# M480_v1 register map
File version: 1.0
Registers are 32-bit, read-write, reset 0x0 unless marked. A register's access mark holds for its fields unless they carry their own. Offsets are from the block's base; [hi:lo] are bit positions; {n}, {i} and the like mark numbered series; 'fields as' and 'values as' point back to an identical list.

## PDMA — PDMA Register Map
Base 0x40008000; alternate view of DSCT_CTL
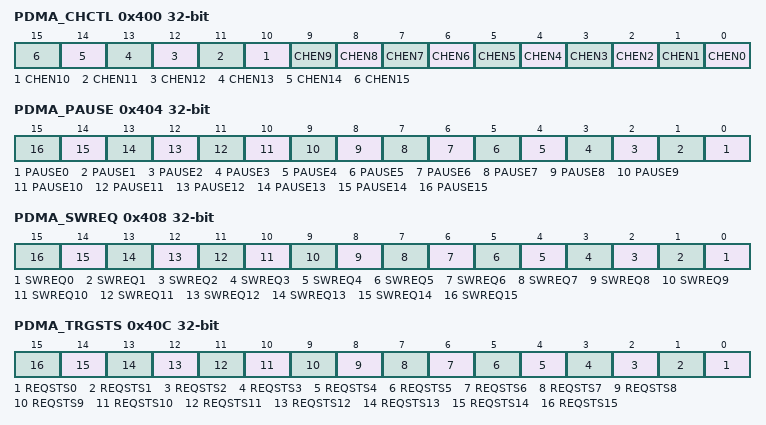
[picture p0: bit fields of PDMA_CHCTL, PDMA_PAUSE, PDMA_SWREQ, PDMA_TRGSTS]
0x400 PDMA_CHCTL — PDMA Channel Control Register
  [all] fields
    0=PDMA channel [n] Disabled; 1=PDMA channel [n] Enabled
  [n] CHEN{n} (n=0..15) — PDMA Channel Enable Bits. Set this bit to 1 to enable PDMAn operation. Channel cannot be active if it is not set as enabled. Note: Setting the corresponding bit of PDMA_PAUSE or PDMA_CHRST register will also clear this bit.
0x404 PDMA_PAUSE wo — PDMA Transfer Pause Control Register
  [all] fields
    0=No effect; 1=Pause PDMA channel n transfer
  [n] PAUSE{n} (n=0..15) — PDMA Channel n Transfer Pause Control (Write Only)
0x408 PDMA_SWREQ wo — PDMA Software Request Register
  [all] fields
    0=No effect; 1=Generate a software request
  [n] SWREQ{n} (n=0..15) — PDMA Software Request (Write Only). Set this bit to 1 to generate a software request to PDMA [n]. Note 1: User can read PDMA_TRGSTS register to know which channel is on active. Active flag may be triggered by software request or peripheral request. Note 2: If user does not enable corresponding PDMA channel, the software request will be ignored.
0x40C PDMA_TRGSTS ro — PDMA Channel Request Status Register
  [all] fields
    0=PDMA Channel n has no request; 1=PDMA Channel n has a request
  [n] REQSTS{n} (n=0..15) — PDMA Channel Request Status (Read Only). This flag indicates whether channel[n] have a request or not, no matter request from software or peripheral. When PDMA controller finishes channel transfer, this bit will be cleared automatically. Note: If user pauses or resets each PDMA transfer by setting PDMA_PAUSE or PDMA_CHRST register respectively, this bit will be cleared automatically after finishing the current transfer.
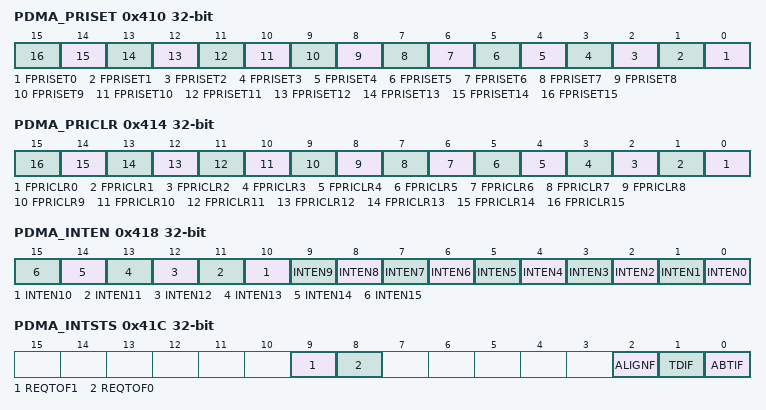
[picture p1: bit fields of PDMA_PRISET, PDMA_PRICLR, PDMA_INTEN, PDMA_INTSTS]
0x410 PDMA_PRISET — PDMA Fixed Priority Setting Register
  [all] fields
    0=No effect. Corresponding PDMA channel is round-robin priority; 1=Set PDMA channel [n] to fixed priority channel. Corresponding PDMA channel is fixed priority
  [n] FPRISET{n} (n=0..15) — PDMA Fixed Priority Setting. Set this bit to 1 to enable fixed priority level. Write Operation: Note: This field only set to fixed priority, clear fixed priority use PDMA_PRICLR register.
0x414 PDMA_PRICLR wo — PDMA Fixed Priority Clear Register
  [all] fields
    0=No effect; 1=Clear PDMA channel [n] fixed priority setting
  [n] FPRICLR{n} (n=0..15) — PDMA Fixed Priority Clear Bits (Write Only). Set this bit to 1 to clear fixed priority level. Note: User can read PDMA_PRISET register to know the channel priority.
0x418 PDMA_INTEN — PDMA Interrupt Enable Register
  [all] fields
    0=PDMA channel n interrupt Disabled; 1=PDMA channel n interrupt Enabled.Note: The interrupt flag is time-out, abort, transfer done and align
  [n] INTEN{n} (n=0..15) — PDMA Interrupt Enable Bits. This field is used to enable PDMA channel[n] interrupt.
0x41C PDMA_INTSTS — PDMA Interrupt Status Register
  [9] REQTOF1 — Request Time-out Flag for Channel 1. This flag indicates that PDMA controller has waited peripheral request for a period defined by PDMA_TOC1, user can write 1 to clear these bits. Note: Please disable time-out function before clear this bit.
    0=No request time-out; 1=Peripheral request time-out
  [8] REQTOF0 — Request Time-out Flag for Channel 0. This flag indicates that PDMA controller has waited peripheral request for a period defined by PDMA_TOC0, user can write 1 to clear these bits. Note: Please disable time-out function before clear this bit.
    0=No request time-out; 1=Peripheral request time-out
  [2] ALIGNF ro — Transfer Alignment Interrupt Flag (Read Only)
    0=PDMA channel source address and destination address both follow transfer width setting; 1=PDMA channel source address or destination address is not follow transfer width setting
  [1] TDIF ro — Transfer Done Interrupt Flag (Read Only). This bit indicates that PDMA controller has finished transmission; User can read PDMA_TDSTS register to indicate which channel finished transfer.
    0=Not finished yet; 1=PDMA channel has finished transmission
  [0] ABTIF ro — PDMA Read/Write Target Abort Interrupt Flag (Read Only). This bit indicates that PDMA has target abort error; Software can read PDMA_ABTSTS register to find which channel has target abort error.
    0=No AHB bus ERROR response received; 1=AHB bus ERROR response received
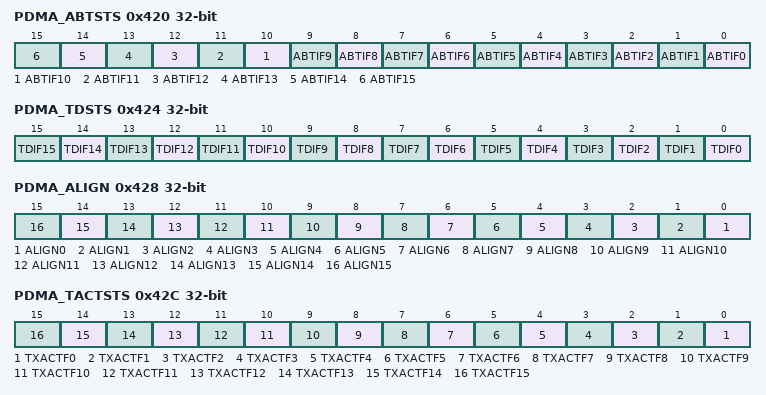
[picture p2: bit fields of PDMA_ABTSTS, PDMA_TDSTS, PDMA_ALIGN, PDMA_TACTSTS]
0x420 PDMA_ABTSTS — PDMA Channel Read/Write Target Abort Flag Register
  [all] fields
    0=No AHB bus ERROR response received when channel n transfer; 1=AHB bus ERROR response received when channel n transfer
  [n] ABTIF{n} (n=0..15) — PDMA Read/Write Target Abort Interrupt Status Flag. This bit indicates which PDMA controller has target abort error; User can write 1 to clear these bits. Note: If channel n target abort, REQSRCn should set 0 to disable peripheral request.
0x424 PDMA_TDSTS — PDMA Channel Transfer Done Flag Register
  [all] fields
    0=PDMA channel transfer has not finished; 1=PDMA channel has finished transmission
  [n] TDIF{n} (n=0..15) — Transfer Done Flag. This bit indicates whether PDMA controller channel transfer has been finished or not, user can write 1 to clear these bits.
0x428 PDMA_ALIGN — PDMA Transfer Alignment Status Register
  [all] fields
    values as PDMA_INTSTS.ALIGNF
  [n] ALIGN{n} (n=0..15) — Transfer Alignment Flag. Note: Source address and destination address should be alignment.
0x42C PDMA_TACTSTS ro — PDMA Transfer Active Flag Register
  [all] fields
    0=PDMA channel is not finished; 1=PDMA channel is active
  [n] TXACTF{n} (n=0..15) — Transfer on Active Flag (Read Only). This bit indicates which PDMA channel is in active.
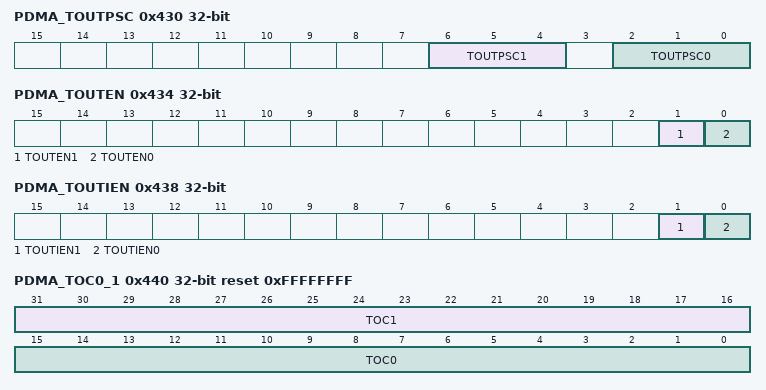
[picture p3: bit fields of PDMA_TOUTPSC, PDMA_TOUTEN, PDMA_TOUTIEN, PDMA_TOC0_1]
0x430 PDMA_TOUTPSC — PDMA Time-out Prescaler Register
  [6:4] TOUTPSC1 — PDMA Channel 1 Time-out Clock Source Prescaler Bits
    0=PDMA channel 1 time-out clock source is HCLK/28; 1=PDMA channel 1 time-out clock source is HCLK/29; {v}=PDMA channel 1 time-out clock source is HCLK/{v+208} (v=2..7)
  [2:0] TOUTPSC0 — PDMA Channel 0 Time-out Clock Source Prescaler Bits
    0=PDMA channel 0 time-out clock source is HCLK/28; 1=PDMA channel 0 time-out clock source is HCLK/29; {v}=PDMA channel 0 time-out clock source is HCLK/{v+208} (v=2..7)
0x434 PDMA_TOUTEN — PDMA Time-out Enable Register
  [1] TOUTEN1 — PDMA Time-out Enable Bits
    0=PDMA Channel n time-out function Disabled; 1=PDMA Channel n time-out function Enabled
  [0] TOUTEN0 — PDMA Time-out Enable Bits
    values as TOUTEN1
0x438 PDMA_TOUTIEN — PDMA Time-out Interrupt Enable Register
  [1] TOUTIEN1 — PDMA Time-out Interrupt Enable Bits
    0=PDMA Channel n time-out interrupt Disabled; 1=PDMA Channel n time-out interrupt Enabled
  [0] TOUTIEN0 — PDMA Time-out Interrupt Enable Bits
    values as TOUTIEN1
0x43C PDMA_SCATBA reset 0x20000000 — PDMA Scatter-gather Descriptor Table Base Address Register
  [31:16] SCATBA — PDMA Scatter-gather Descriptor Table Address. In Scatter-Gather mode, this is the base address for calculating the next link - list address. The next link address equation is. Note: Only useful in Scatter-Gather mode.
0x440 PDMA_TOC0_1 reset 0xFFFFFFFF — PDMA Time-out Counter Ch1 and Ch0 Register
  [31:16] TOC1 — Time-out Counter for Channel 1. This controls the period of time-out function for channel 1. The calculation unit is based on 10 kHz clock. The example of time-out period can refer TOC0 bit description.
  [15:0] TOC0 — Time-out Counter for Channel 0. This controls the period of time-out function for channel 0. The calculation unit is based on TOUTPSC0 (PDMA_TOUTPSC[2:0]) clock.
0x460 PDMA_CHRST — PDMA Channel Reset Register
  [15:0] CHnRST — Channel n Reset. Note: This function don't support stride mode.
    0=corresponding channel n is not reset; 1=corresponding channel n is reset
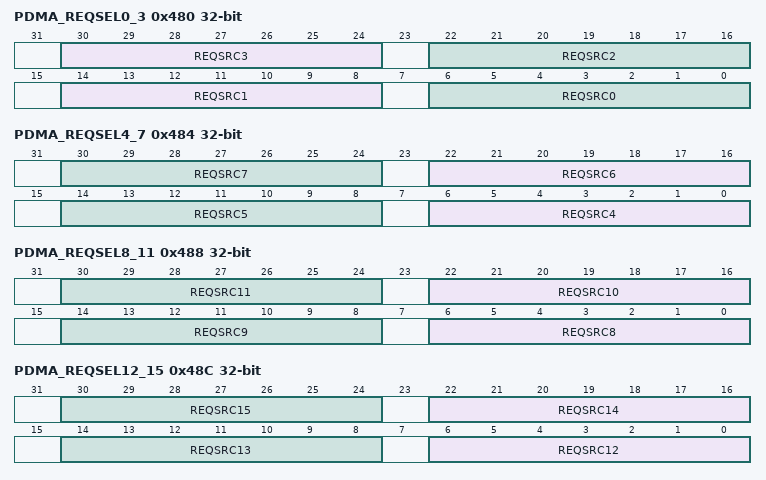
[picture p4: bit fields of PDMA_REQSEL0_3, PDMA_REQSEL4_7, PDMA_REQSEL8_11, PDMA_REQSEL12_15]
0x480 PDMA_REQSEL0_3 — PDMA Request Source Select Register 0
  [30:24] REQSRC3 — Channel 3 Request Source Selection. This filed defines which peripheral is connected to PDMA channel 3. User can configure the peripheral setting by REQSRC3. Note: The channel configuration is the same as REQSRC0 field. Please refer to the explanation of REQSRC0.
  [22:16] REQSRC2 — Channel 2 Request Source Selection. This filed defines which peripheral is connected to PDMA channel 2. User can configure the peripheral setting by REQSRC2. Note: The channel configuration is the same as REQSRC0 field. Please refer to the explanation of REQSRC0.
  [14:8] REQSRC1 — Channel 1 Request Source Selection. This filed defines which peripheral is connected to PDMA channel 1. User can configure the peripheral setting by REQSRC1. Note: The channel configuration is the same as REQSRC0 field. Please refer to the explanation of REQSRC0.
  [6:0] REQSRC0 — Channel 0 Request Source Selection. This filed defines which peripheral is connected to PDMA channel 0. User can configure the peripheral by setting REQSRC0. Note 1: A peripheral cannot be assigned to two channels at the same time. Note 2: This field is useless when transfer between memory and memory.
    0=Disable PDMA peripheral request; 2=Channel connects to USB_TX; 3=Channel connects to USB_RX; 4=Channel connects to UART0_TX; 5=Channel connects to UART0_RX; 6=Channel connects to UART1_TX; 7=Channel connects to UART1_RX; 8=Channel connects to UART2_TX; 9=Channel connects to UART2_RX; 10=Channel connects to UART3_TX; 11=Channel connects to UART3_RX; 12=Channel connects to UART4_TX; 13=Channel connects to UART4_RX; 14=Channel connects to UART5_TX; 15=Channel connects to UART5_RX; 16=Channel connects to USCI0_TX; 17=Channel connects to USCI0_RX; 18=Channel connects to USCI1_TX; 19=Channel connects to USCI1_RX; 20=Channel connects to QSPI0_TX; 21=Channel connects to QSPI0_RX; 22=Channel connects to SPI0_TX; 23=Channel connects to SPI0_RX; 24=Channel connects to SPI1_TX; 25=Channel connects to SPI1_RX; 26=Channel connects to SPI2_TX; 27=Channel connects to SPI2_RX; 28=Channel connects to SPI3_TX; 29=Channel connects to SPI3_RX; 30=Channel connects to QSPI1_TX; 31=Channel connects to QSPI1_RX; 32=Channel connects to EPWM0_P1_RX; 33=Channel connects to EPWM0_P2_RX; 34=Channel connects to EPWM0_P3_RX; 35=Channel connects to EPWM1_P1_RX; 36=Channel connects to EPWM1_P2_RX; 37=Channel connects to EPWM1_P3_RX; 38=Channel connects to I2C0_TX; 39=Channel connects to I2C0_RX; 40=Channel connects to I2C1_TX; 41=Channel connects to I2C1_RX; 42=Channel connects to I2C2_TX; 43=Channel connects to I2C2_RX; 44=Channel connects to I2S0_TX; 45=Channel connects to I2S0_RX; {v}=Channel connects to TMR{v-46} (v=46..49); 50=Channel connects to EADC0_RX; 51=Channel connects to DAC0_TX; 52=Channel connects to DAC1_TX; {v}=Channel connects to EPWM0_CH{v-53}_TX (v=53..58); {v}=Channel connects to EPWM1_CH{v-59}_TX (v=59..64); 66=Channel connects to UART6_TX; 67=Channel connects to UART6_RX; 68=Channel connects to UART7_TX; 69=Channel connects to UART7_RX; 70=Channel connects to EADC1_RX
0x484 PDMA_REQSEL4_7 — PDMA Request Source Select Register 1
  [8n-26:8n-32] REQSRC{n} (n=4..7) — Channel {n} Request Source Selection. This filed defines which peripheral is connected to PDMA channel {n}. User can configure the peripheral setting by REQSRC{n}. Note: The channel configuration is the same as REQSRC0 field. Please refer to the explanation of REQSRC0.
0x488 PDMA_REQSEL8_11 — PDMA Request Source Select Register 2
  [8n-58:8n-64] REQSRC{n} (n=8..11) — Channel {n} Request Source Selection. This filed defines which peripheral is connected to PDMA channel {n}. User can configure the peripheral setting by REQSRC{n}. Note: The channel configuration is the same as REQSRC0 field. Please refer to the explanation of REQSRC0.
0x48C PDMA_REQSEL12_15 — PDMA Request Source Select Register 3
  [8n-90:8n-96] REQSRC{n} (n=12..15) — Channel {n} Request Source Selection. This filed defines which peripheral is connected to PDMA channel {n}. User can configure the peripheral setting by REQSRC{n}. Note: The channel configuration is the same as REQSRC0 field. Please refer to the explanation of REQSRC0.
{0x500+8i} PDMA_STC{i} (i=0..5) — Stride Transfer Count Register of PDMA Channel {i}
  [15:0] STC — PDMA Stride Transfer Count. The 16-bit register defines the stride transfer count of each row, the real transfer count is (STC + 1).
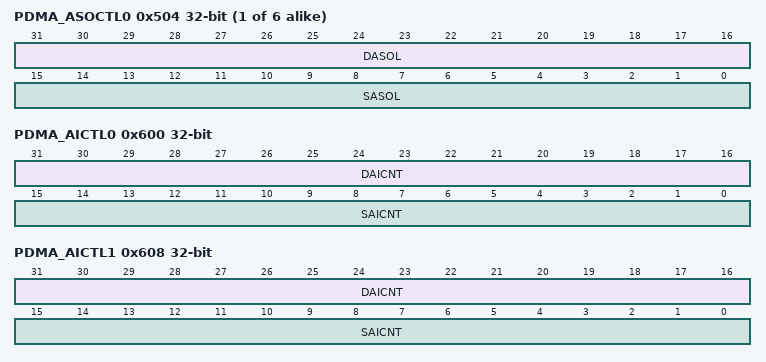
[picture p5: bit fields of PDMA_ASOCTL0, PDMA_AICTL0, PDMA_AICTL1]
{0x504+8i} PDMA_ASOCTL{i} (i=0..5) — Address Stride Offset Control Register of PDMA Channel {i}
  [31:16] DASOL — PDMA Destination Address Stride Offset Length. The 16-bit register defines the destination address stride transfer offset count of each row.
  [15:0] SASOL — PDMA Source Address Stride Offset Length. The 16-bit register defines the source address stride transfer offset count of each row.
0x600 PDMA_AICTL0 — Address Interval Control Register of PDMA Channel 0
  [31:16] DAICNT — PDMA Destination Address Interval Count. The 16-bit register defines the destination address interval count of each row. Note: This register should be set to 0 when repeat count(PDMA_RCNTn) set to 0.
  [15:0] SAICNT — PDMA Source Address Interval Count. The 16-bit register defines the source address interval count of each row. Note: This register should be set to 0 when repeat count(PDMA_RCNTn) set to 0.
0x604 PDMA_RCNT0 — Repeat Count Register of PDMA Channel 0
  [15:0] RCNT — PDMA Repeat Count. The 16-bit register defines the repeat times of block transfer. Note: This register should be set to 0 when stride function disabled.
0x608 PDMA_AICTL1 — Address Interval Control Register of PDMA Channel 1
  fields as PDMA_AICTL0
0x60C PDMA_RCNT1 — Repeat Count Register of PDMA Channel 1
  fields as PDMA_RCNT0
